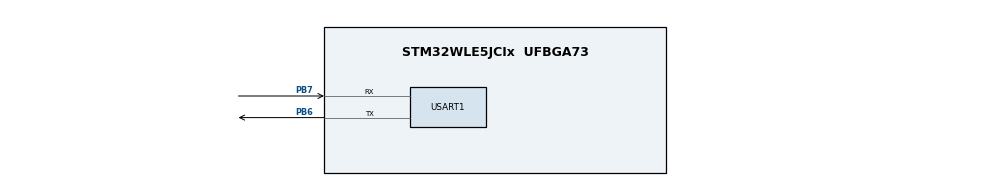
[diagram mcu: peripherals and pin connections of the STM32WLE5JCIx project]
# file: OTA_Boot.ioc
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Mcu.Family=STM32WL
Mcu.Name=STM32WLE5JCIx
Mcu.Package=UFBGA73
NVIC.PriorityGroup=NVIC_PRIORITYGROUP_4
PB6.Mode=Multiprocessor_communication
PB6.Signal=USART1_TX
PB7.Mode=Multiprocessor_communication
PB7.Signal=USART1_RX
ProjectManager.HeapSize=0x200
ProjectManager.StackSize=0x400
ProjectManager.TargetToolchain=STM32CubeIDE
RCC.HSE_VALUE=8000000
RCC.HSI_VALUE=16000000
RCC.LSE_VALUE=32768
RCC.VCOOutputFreq_Value=32000000
USART1.VirtualMode-Multiprocessor_communication=VM_ASYNC
VP_CRC_VS_CRC.Mode=CRC_Activate
board=custom

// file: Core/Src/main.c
/* USER CODE BEGIN Header */
/**
  ******************************************************************************
  * @file           : main.c
  * @brief          : Main program body
  ******************************************************************************
  * @attention
  *
  * <h2><center>&copy; Copyright (c) 2021 STMicroelectronics.
  * All rights reserved.</center></h2>
  *
  * This software component is licensed by ST under BSD 3-Clause license,
  * the "License"; You may not use this file except in compliance with the
  * License. You may obtain a copy of the License at:
  *                        opensource.org/licenses/BSD-3-Clause
  *
  ******************************************************************************
  */
/* USER CODE END Header */
#include "main.h"

/* USER CODE BEGIN Includes */
#include <string.h>
#include "flash_if.h"
#include "ymodem.h"
#include "common.h"
/* USER CODE END Includes */

CRC_HandleTypeDef hcrc;

UART_HandleTypeDef huart1;

/* USER CODE BEGIN PV */
uint32_t JumpAddr;
pFunction JumpToApp;
SystemParamTypeDef SystemParam_default = {
		.Device_id      = 0x00000001,
		.Hardware_Version 		= 0x10000001,
		.App_Version 	= 0x00000000,
		.App_Status 	= 0,
};
uint32_t APP_ADDR[2] = { APP1_ADDR, APP2_ADDR};
SystemParamTypeDef SystemParam;
/* USER CODE END PV */

void SystemClock_Config(void);
static void MX_CRC_Init(void);
static void MX_GPIO_Init(void);
static void MX_USART1_UART_Init(void);

/* USER CODE BEGIN 0 */
uint32_t System_ParamUpdate(uint32_t addr, SystemParamTypeDef *pData)
{
  if(addr != SYSTEMPARAM_ADDR) //&& addr != SYSTEMPARAM_BACKUPADDR)
    return 1;

  if(FLASH_If_Erase(addr, 1) != 0)
    return 1;

  if(FLASH_If_Write(addr, (uint32_t*)pData, sizeof(SystemParamTypeDef) / 4) != HAL_OK)
    return 1;

    return 0;
}
uint32_t System_SelectBootAddr(SystemParamTypeDef *pData)
{
  uint32_t size = 0;
  FLASH_If_Read(SYSTEMPARAM_ADDR, (uint32_t*)pData, sizeof(SystemParamTypeDef) / 4);
  if(pData->App_Status > 1 || pData->App_Version == 0xFFFFFFFF)
  {	 /* 第一次烧录是写入默认信息 */
	 memcpy(pData, &SystemParam_default, sizeof(SystemParamTypeDef));
  }
  else if(pData->App_Version == TEST_VERSION)
  {
    /* 如果版本号为dddddddd，即更新后第一次运行失败 */
    pData->App_Status = 1 - pData->App_Status;
  }
  else if(pData->App_Version == UPDATE_VERSION)
  {
    pData->App_Status = 1 - pData->App_Status;
    Ymodem_Receive( &size );
    pData->App_Version = TEST_VERSION;
  }
  System_ParamUpdate(SYSTEMPARAM_ADDR, pData);
  //printf("\n\n\rApp_Status  1\n\r", &pData->App_Status);
  return APP_ADDR[pData->App_Status];
}
/* USER CODE END 0 */

int main(void)
{

  /* MCU Configuration--------------------------------------------------------*/

  /* Reset of all peripherals, Initializes the Flash interface and the Systick. */
  HAL_Init();

  /* Configure the system clock */
  SystemClock_Config();

  /* Initialize all configured peripherals */
  MX_CRC_Init();
  MX_GPIO_Init();
  MX_USART1_UART_Init();
  /* USER CODE BEGIN 2 */
  /* execute the new program */
  //HAL_IWDG_Refresh(&hiwdg);
  JumpAddr = System_SelectBootAddr(&SystemParam);
  JumpAddr = *(__IO uint32_t*) (JumpAddr + 4);

  HAL_UART_DeInit(&huart1);
  HAL_SuspendTick();
  /* Refresh the IWDG. */
  //HAL_IWDG_Refresh(&hiwdg);
  /* Jump to user application */
  JumpToApp = (pFunction) JumpAddr;
  /* Initialize user application's Stack Pointer */
  __set_MSP(*(__IO uint32_t*) (JumpAddr - 4));
  JumpToApp();
  /* USER CODE END 2 */

  /* Infinite loop */
  while (1)
  {

  }
}

void SystemClock_Config(void)
{
  RCC_OscInitTypeDef RCC_OscInitStruct = {0};
  RCC_ClkInitTypeDef RCC_ClkInitStruct = {0};

  /** Configure the main internal regulator output voltage
  */
  __HAL_PWR_VOLTAGESCALING_CONFIG(PWR_REGULATOR_VOLTAGE_SCALE2);
  /** Initializes the CPU, AHB and APB busses clocks
  */
  RCC_OscInitStruct.OscillatorType = RCC_OSCILLATORTYPE_MSI;
  RCC_OscInitStruct.MSIState = RCC_MSI_ON;
  RCC_OscInitStruct.MSICalibrationValue = RCC_MSICALIBRATION_DEFAULT;
  RCC_OscInitStruct.MSIClockRange = RCC_MSIRANGE_6;
  RCC_OscInitStruct.PLL.PLLState = RCC_PLL_NONE;
  if (HAL_RCC_OscConfig(&RCC_OscInitStruct) != HAL_OK)
  {
    Error_Handler();
  }
  /** Configure the SYSCLKSource, HCLK, PCLK1 and PCLK2 clocks dividers
  */
  RCC_ClkInitStruct.ClockType = RCC_CLOCKTYPE_HCLK3|RCC_CLOCKTYPE_HCLK
                              |RCC_CLOCKTYPE_SYSCLK|RCC_CLOCKTYPE_PCLK1
                              |RCC_CLOCKTYPE_PCLK2;
  RCC_ClkInitStruct.SYSCLKSource = RCC_SYSCLKSOURCE_MSI;
  RCC_ClkInitStruct.AHBCLKDivider = RCC_SYSCLK_DIV1;
  RCC_ClkInitStruct.APB1CLKDivider = RCC_HCLK_DIV1;
  RCC_ClkInitStruct.APB2CLKDivider = RCC_HCLK_DIV1;
  RCC_ClkInitStruct.AHBCLK3Divider = RCC_SYSCLK_DIV1;

  if (HAL_RCC_ClockConfig(&RCC_ClkInitStruct, FLASH_LATENCY_0) != HAL_OK)
  {
    Error_Handler();
  }
}

static void MX_CRC_Init(void)
{

  hcrc.Instance = CRC;
  hcrc.Init.DefaultPolynomialUse = DEFAULT_POLYNOMIAL_ENABLE;
  hcrc.Init.DefaultInitValueUse = DEFAULT_INIT_VALUE_ENABLE;
  hcrc.Init.InputDataInversionMode = CRC_INPUTDATA_INVERSION_NONE;
  hcrc.Init.OutputDataInversionMode = CRC_OUTPUTDATA_INVERSION_DISABLE;
  hcrc.InputDataFormat = CRC_INPUTDATA_FORMAT_BYTES;
  if (HAL_CRC_Init(&hcrc) != HAL_OK)
  {
    Error_Handler();
  }

}

static void MX_USART1_UART_Init(void)
{

  huart1.Instance = USART1;
  huart1.Init.BaudRate = 115200;
  huart1.Init.WordLength = UART_WORDLENGTH_8B;
  huart1.Init.StopBits = UART_STOPBITS_1;
  huart1.Init.Parity = UART_PARITY_NONE;
  huart1.Init.Mode = UART_MODE_TX_RX;
  huart1.Init.HwFlowCtl = UART_HWCONTROL_NONE;
  huart1.Init.OverSampling = UART_OVERSAMPLING_16;
  huart1.Init.OneBitSampling = UART_ONE_BIT_SAMPLE_DISABLE;
  huart1.Init.ClockPrescaler = UART_PRESCALER_DIV1;
  huart1.AdvancedInit.AdvFeatureInit = UART_ADVFEATURE_NO_INIT;
  if (HAL_MultiProcessor_Init(&huart1, 0, UART_WAKEUPMETHOD_IDLELINE) != HAL_OK)
  {
    Error_Handler();
  }
  if (HAL_UARTEx_SetTxFifoThreshold(&huart1, UART_TXFIFO_THRESHOLD_1_8) != HAL_OK)
  {
    Error_Handler();
  }
  if (HAL_UARTEx_SetRxFifoThreshold(&huart1, UART_RXFIFO_THRESHOLD_1_8) != HAL_OK)
  {
    Error_Handler();
  }
  if (HAL_UARTEx_DisableFifoMode(&huart1) != HAL_OK)
  {
    Error_Handler();
  }

}

static void MX_GPIO_Init(void)
{

  /* GPIO Ports Clock Enable */
  __HAL_RCC_GPIOB_CLK_ENABLE();

}

/* USER CODE BEGIN 4 */
int __io_putchar(int ch)
{
	HAL_UART_Transmit(&huart1, (uint8_t*)&ch, 1, 1000);
	return ch;
}
/* USER CODE END 4 */

void Error_Handler(void)
{
  __disable_irq();
  while (1)
  {
  }
}

/************************ (C) COPYRIGHT STMicroelectronics *****END OF FILE****/
